AUTOSAR XML (schema 4-0-3)
package /App_IoHwAb
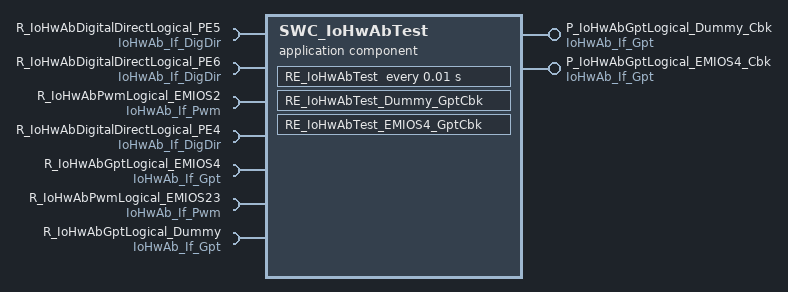
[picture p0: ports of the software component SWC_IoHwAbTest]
  application sw component type SWC_IoHwAbTest
    require port R_IoHwAbDigitalDirectLogical_PE5: required-com-specs=[ReadDirect, WriteDirect, SetToInput, SetToOutput, IsInput, IsOutput], required-interface=IoHwAb_If_DigDir
    provide port P_IoHwAbGptLogical_Dummy_Cbk: server-com-spec{operation=Notification, queue-length=1}, provided-interface=IoHwAb_If_Gpt
    5 x require port:
      R_IoHwAbDigitalDirectLogical_PE6: required-com-specs=[IsInput, IsOutput, ReadDirect, SetToInput, SetToOutput, WriteDirect], required-interface=IoHwAb_If_DigDir
      R_IoHwAbPwmLogical_EMIOS2: required-com-specs=[SetDutyCycle, SetPeriodAndDuty, SetOutputToIdle, GetOutputState, DisableNotification, EnableNotification], required-interface=IoHwAb_If_Pwm
      R_IoHwAbDigitalDirectLogical_PE4: required-com-specs=[ReadDirect, WriteDirect, SetToInput, SetToOutput, IsInput, IsOutput], required-interface=IoHwAb_If_DigDir
      R_IoHwAbGptLogical_EMIOS4: required-com-specs=[StartTimer, StopTimer, GetTimeElapsed, GetTimeRemaining, DisableNotification, EnableNotification], required-interface=IoHwAb_If_Gpt
      R_IoHwAbPwmLogical_EMIOS23: required-com-specs=[SetDutyCycle, SetPeriodAndDuty, SetOutputToIdle, GetOutputState, DisableNotification, EnableNotification], required-interface=IoHwAb_If_Pwm
    provide port P_IoHwAbGptLogical_EMIOS4_Cbk: server-com-spec{operation=Notification, queue-length=1}, provided-interface=IoHwAb_If_Gpt
    require port R_IoHwAbGptLogical_Dummy: required-com-specs=[StartTimer, StopTimer, GetTimeElapsed, GetTimeRemaining, DisableNotification, EnableNotification], required-interface=IoHwAb_If_Gpt
    behavior SwcIB_IoHwAbTest
      timing event TE_IoHwAbTest: start-on-event=RE_IoHwAbTest, period=0.01
      operation invoked event OIE_RE_IoHwAbTest_EMIOS4_GptCbk_RE_IoHwAbTest_EMIOS4_GptCbk_Notification: start-on-event=RE_IoHwAbTest_EMIOS4_GptCbk, operation=P_IoHwAbGptLogical_EMIOS4_Cbk.Notification
      runnable RE_IoHwAbTest
        44 x sync call:
          SSCP_RE_IoHwAbTest_R_IoHwAbDigitalDirectLogical_PE4_IsInput: operation=R_IoHwAbDigitalDirectLogical_PE4.IsInput
          SSCP_RE_IoHwAbTest_R_IoHwAbDigitalDirectLogical_PE4_IsOutput: operation=R_IoHwAbDigitalDirectLogical_PE4.IsOutput
          SSCP_RE_IoHwAbTest_R_IoHwAbDigitalDirectLogical_PE4_ReadDirect: operation=R_IoHwAbDigitalDirectLogical_PE4.ReadDirect
          SSCP_RE_IoHwAbTest_R_IoHwAbDigitalDirectLogical_PE4_SetToInput: operation=R_IoHwAbDigitalDirectLogical_PE4.SetToInput
          SSCP_RE_IoHwAbTest_R_IoHwAbDigitalDirectLogical_PE4_SetToOutput: operation=R_IoHwAbDigitalDirectLogical_PE4.SetToOutput
          SSCP_RE_IoHwAbTest_R_IoHwAbDigitalDirectLogical_PE4_WriteDirect: operation=R_IoHwAbDigitalDirectLogical_PE4.WriteDirect
          SSCP_RE_IoHwAbTest_R_IoHwAbDigitalDirectLogical_PE5_IsInput: operation=R_IoHwAbDigitalDirectLogical_PE5.IsInput
          SSCP_RE_IoHwAbTest_R_IoHwAbDigitalDirectLogical_PE5_IsOutput: operation=R_IoHwAbDigitalDirectLogical_PE5.IsOutput
          SSCP_RE_IoHwAbTest_R_IoHwAbDigitalDirectLogical_PE5_ReadDirect: operation=R_IoHwAbDigitalDirectLogical_PE5.ReadDirect
          SSCP_RE_IoHwAbTest_R_IoHwAbDigitalDirectLogical_PE5_SetToInput: operation=R_IoHwAbDigitalDirectLogical_PE5.SetToInput
          SSCP_RE_IoHwAbTest_R_IoHwAbDigitalDirectLogical_PE5_SetToOutput: operation=R_IoHwAbDigitalDirectLogical_PE5.SetToOutput
          SSCP_RE_IoHwAbTest_R_IoHwAbDigitalDirectLogical_PE5_WriteDirect: operation=R_IoHwAbDigitalDirectLogical_PE5.WriteDirect
          SSCP_RE_IoHwAbTest_R_IoHwAbDigitalDirectLogical_PE6_IsInput: operation=R_IoHwAbDigitalDirectLogical_PE6.IsInput
          SSCP_RE_IoHwAbTest_R_IoHwAbDigitalDirectLogical_PE6_IsOutput: operation=R_IoHwAbDigitalDirectLogical_PE6.IsOutput
          SSCP_RE_IoHwAbTest_R_IoHwAbDigitalDirectLogical_PE6_ReadDirect: operation=R_IoHwAbDigitalDirectLogical_PE6.ReadDirect
          SSCP_RE_IoHwAbTest_R_IoHwAbDigitalDirectLogical_PE6_SetToInput: operation=R_IoHwAbDigitalDirectLogical_PE6.SetToInput
          SSCP_RE_IoHwAbTest_R_IoHwAbDigitalDirectLogical_PE6_SetToOutput: operation=R_IoHwAbDigitalDirectLogical_PE6.SetToOutput
          SSCP_RE_IoHwAbTest_R_IoHwAbDigitalDirectLogical_PE6_WriteDirect: operation=R_IoHwAbDigitalDirectLogical_PE6.WriteDirect
          SSCP_RE_IoHwAbTest_R_IoHwAbGptLogical_Dummy_DisableNotification: operation=R_IoHwAbGptLogical_Dummy.DisableNotification
          SSCP_RE_IoHwAbTest_R_IoHwAbGptLogical_Dummy_EnableNotification: operation=R_IoHwAbGptLogical_Dummy.EnableNotification
          SSCP_RE_IoHwAbTest_R_IoHwAbGptLogical_Dummy_GetTimeElapsed: operation=R_IoHwAbGptLogical_Dummy.GetTimeElapsed
          SSCP_RE_IoHwAbTest_R_IoHwAbGptLogical_Dummy_GetTimeRemaining: operation=R_IoHwAbGptLogical_Dummy.GetTimeRemaining
          SSCP_RE_IoHwAbTest_R_IoHwAbGptLogical_Dummy_Notification: operation=R_IoHwAbGptLogical_Dummy.Notification, timeout=0.0
          SSCP_RE_IoHwAbTest_R_IoHwAbGptLogical_Dummy_StartTimer: operation=R_IoHwAbGptLogical_Dummy.StartTimer
          SSCP_RE_IoHwAbTest_R_IoHwAbGptLogical_Dummy_StopTimer: operation=R_IoHwAbGptLogical_Dummy.StopTimer
          SSCP_RE_IoHwAbTest_R_IoHwAbGptLogical_EMIOS4_DisableNotification: operation=R_IoHwAbGptLogical_EMIOS4.DisableNotification
          SSCP_RE_IoHwAbTest_R_IoHwAbGptLogical_EMIOS4_EnableNotification: operation=R_IoHwAbGptLogical_EMIOS4.EnableNotification
          SSCP_RE_IoHwAbTest_R_IoHwAbGptLogical_EMIOS4_GetTimeElapsed: operation=R_IoHwAbGptLogical_EMIOS4.GetTimeElapsed
          SSCP_RE_IoHwAbTest_R_IoHwAbGptLogical_EMIOS4_GetTimeRemaining: operation=R_IoHwAbGptLogical_EMIOS4.GetTimeRemaining
          SSCP_RE_IoHwAbTest_R_IoHwAbGptLogical_EMIOS4_Notification: operation=R_IoHwAbGptLogical_EMIOS4.Notification, timeout=0.0
          SSCP_RE_IoHwAbTest_R_IoHwAbGptLogical_EMIOS4_StartTimer: operation=R_IoHwAbGptLogical_EMIOS4.StartTimer
          SSCP_RE_IoHwAbTest_R_IoHwAbGptLogical_EMIOS4_StopTimer: operation=R_IoHwAbGptLogical_EMIOS4.StopTimer
          SSCP_RE_IoHwAbTest_R_IoHwAbPwmLogical_EMIOS23_DisableNotification: operation=R_IoHwAbPwmLogical_EMIOS23.DisableNotification
          SSCP_RE_IoHwAbTest_R_IoHwAbPwmLogical_EMIOS23_EnableNotification: operation=R_IoHwAbPwmLogical_EMIOS23.EnableNotification
          SSCP_RE_IoHwAbTest_R_IoHwAbPwmLogical_EMIOS23_GetOutputState: operation=R_IoHwAbPwmLogical_EMIOS23.GetOutputState
          SSCP_RE_IoHwAbTest_R_IoHwAbPwmLogical_EMIOS23_SetDutyCycle: operation=R_IoHwAbPwmLogical_EMIOS23.SetDutyCycle
          SSCP_RE_IoHwAbTest_R_IoHwAbPwmLogical_EMIOS23_SetOutputToIdle: operation=R_IoHwAbPwmLogical_EMIOS23.SetOutputToIdle
          SSCP_RE_IoHwAbTest_R_IoHwAbPwmLogical_EMIOS23_SetPeriodAndDuty: operation=R_IoHwAbPwmLogical_EMIOS23.SetPeriodAndDuty
          SSCP_RE_IoHwAbTest_R_IoHwAbPwmLogical_EMIOS2_DisableNotification: operation=R_IoHwAbPwmLogical_EMIOS2.DisableNotification
          SSCP_RE_IoHwAbTest_R_IoHwAbPwmLogical_EMIOS2_EnableNotification: operation=R_IoHwAbPwmLogical_EMIOS2.EnableNotification
          SSCP_RE_IoHwAbTest_R_IoHwAbPwmLogical_EMIOS2_GetOutputState: operation=R_IoHwAbPwmLogical_EMIOS2.GetOutputState
          SSCP_RE_IoHwAbTest_R_IoHwAbPwmLogical_EMIOS2_SetDutyCycle: operation=R_IoHwAbPwmLogical_EMIOS2.SetDutyCycle
          SSCP_RE_IoHwAbTest_R_IoHwAbPwmLogical_EMIOS2_SetOutputToIdle: operation=R_IoHwAbPwmLogical_EMIOS2.SetOutputToIdle
          SSCP_RE_IoHwAbTest_R_IoHwAbPwmLogical_EMIOS2_SetPeriodAndDuty: operation=R_IoHwAbPwmLogical_EMIOS2.SetPeriodAndDuty
      runnable RE_IoHwAbTest_Dummy_GptCbk
        sync call SSCP_RE_IoHwAbTest_Dummy_GptCbk_R_IoHwAbGptLogical_Dummy_Notification: operation=R_IoHwAbGptLogical_Dummy.Notification, timeout=0.0
      runnable RE_IoHwAbTest_EMIOS4_GptCbk
        sync call SSCP_RE_IoHwAbTest_EMIOS4_GptCbk_R_IoHwAbGptLogical_EMIOS4_Notification: operation=R_IoHwAbGptLogical_EMIOS4.Notification
